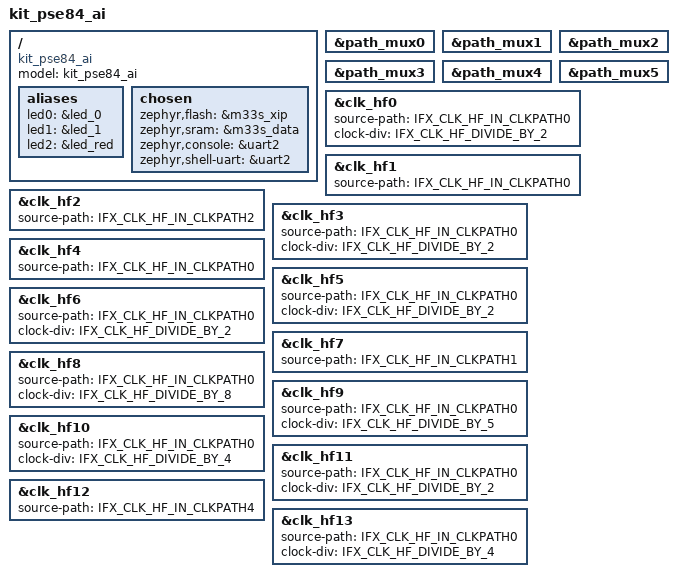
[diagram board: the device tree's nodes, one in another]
/*
 * Copyright (c) 2025 Infineon Technologies AG,
 * or an affiliate of Infineon Technologies AG.
 *
 * SPDX-License-Identifier: Apache-2.0
 */

/dts-v1/;
#include <infineon/edge/mpns/pse846gps2dbzc4a_s.dtsi>
#include <infineon/edge/pse84/pse84.cm33.dtsi>
#include <infineon/edge/pse84/system_clocks.dtsi>

#include "kit_pse84_ai_common.dtsi"
#include "kit_pse84_ai_memory_map.dtsi"

/ {
	model = "kit_pse84_ai";
	compatible = "kit_pse84_ai";

	aliases {
		led0 = &led_0;
		led1 = &led_1;
		led2 = &led_red;
	};

	chosen {
		zephyr,flash = &m33s_xip;
		zephyr,sram = &m33s_data;
		zephyr,console = &uart2;
		zephyr,shell-uart = &uart2;
	};
};

&path_mux0 {
	status = "okay";
};

&path_mux1 {
	status = "okay";
};

&path_mux2 {
	status = "okay";
};

&path_mux3 {
	status = "okay";
};

&path_mux4 {
	status = "okay";
};

&path_mux5 {
	status = "okay";
};

&clk_hf0 {
	source-path = <IFX_CLK_HF_IN_CLKPATH0>;
	clock-div = <IFX_CLK_HF_DIVIDE_BY_2>;
	status = "okay";
};

&clk_hf1 {
	source-path = <IFX_CLK_HF_IN_CLKPATH0>;
	status = "okay";
};

&clk_hf2 {
	source-path = <IFX_CLK_HF_IN_CLKPATH2>;
	status = "okay";
};

&clk_hf3 {
	source-path = <IFX_CLK_HF_IN_CLKPATH0>;
	clock-div = <IFX_CLK_HF_DIVIDE_BY_2>;
	status = "okay";
};

&clk_hf4 {
	source-path = <IFX_CLK_HF_IN_CLKPATH0>;
	status = "okay";
};

&clk_hf5 {
	source-path = <IFX_CLK_HF_IN_CLKPATH0>;
	clock-div = <IFX_CLK_HF_DIVIDE_BY_2>;
	status = "okay";
};

&clk_hf6 {
	source-path = <IFX_CLK_HF_IN_CLKPATH0>;
	clock-div = <IFX_CLK_HF_DIVIDE_BY_2>;
	status = "okay";
};

&clk_hf7 {
	source-path = <IFX_CLK_HF_IN_CLKPATH1>;
	status = "okay";
};

&clk_hf8 {
	source-path = <IFX_CLK_HF_IN_CLKPATH0>;
	clock-div = <IFX_CLK_HF_DIVIDE_BY_8>;
	status = "okay";
};

&clk_hf9 {
	source-path = <IFX_CLK_HF_IN_CLKPATH0>;
	clock-div = <IFX_CLK_HF_DIVIDE_BY_5>;
	status = "okay";
};

&clk_hf10 {
	source-path = <IFX_CLK_HF_IN_CLKPATH0>;
	clock-div = <IFX_CLK_HF_DIVIDE_BY_4>;
	status = "okay";
};

&clk_hf11 {
	source-path = <IFX_CLK_HF_IN_CLKPATH0>;
	clock-div = <IFX_CLK_HF_DIVIDE_BY_2>;
	status = "okay";
};

&clk_hf12 {
	source-path = <IFX_CLK_HF_IN_CLKPATH4>;
	status = "okay";
};

&clk_hf13 {
	source-path = <IFX_CLK_HF_IN_CLKPATH0>;
	clock-div = <IFX_CLK_HF_DIVIDE_BY_4>;
	status = "okay";
};
